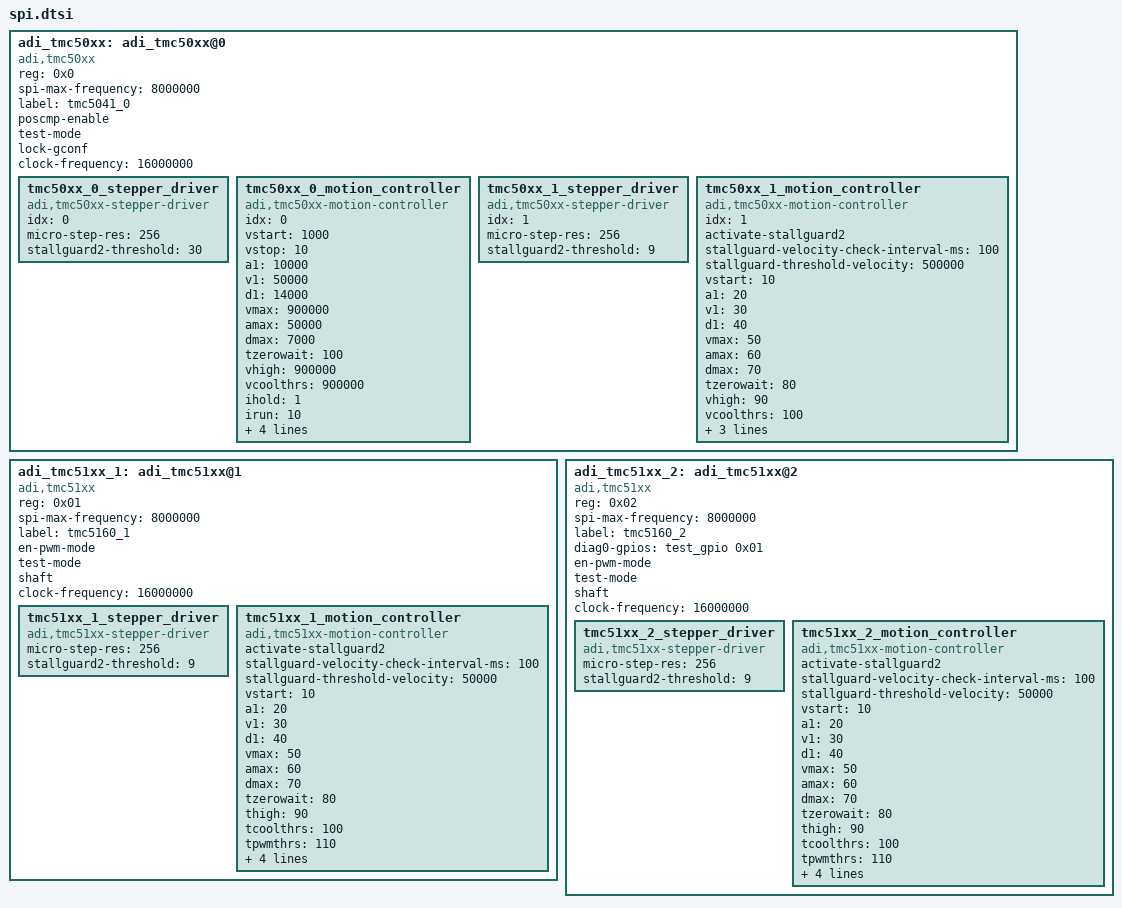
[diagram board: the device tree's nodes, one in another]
/*
 * SPDX-FileCopyrightText: Copyright (c) 2024 Carl Zeiss Meditec AG
 * SPDX-License-Identifier: Apache-2.0
 */
/****************************************
 * PLEASE KEEP REG ADDRESSES SEQUENTIAL *
 ***************************************/

#include <zephyr/dt-bindings/gpio/gpio.h>

adi_tmc50xx: adi_tmc50xx@0 {
	compatible = "adi,tmc50xx";
	status = "okay";
	reg = <0x0>;
	spi-max-frequency = <8000000>;
	label = "tmc5041_0";

	poscmp-enable; test-mode; lock-gconf; /* ADI TMC Global configuration flags */
	clock-frequency = <16000000>; /* Internal/External Clock frequency */

	/* common stepper controller settings */
	tmc50xx_0_stepper_driver: tmc50xx_0_stepper_driver {
		idx = <0>;
		compatible = "adi,tmc50xx-stepper-driver";
		micro-step-res = <256>;
		/* ADI TMC stallguard settings specific to TMC50XX */
		stallguard2-threshold=<30>;
	};

	/* ADI TMC ramp generator as well as current settings */
	tmc50xx_0_motion_controller: tmc50xx_0_motion_controller {
		idx = <0>;
		compatible = "adi,tmc50xx-motion-controller";
		vstart = <1000>;
		vstop = <10>;
		a1 = <10000>;
		v1 = <50000>;
		d1 = <14000>;
		vmax = <900000>;
		amax = <50000>;
		dmax = <7000>;
		tzerowait = <100>;
		vhigh = <900000>;
		vcoolthrs = <900000>;
		ihold = <1>;
		irun = <10>;
		iholddelay = <1>;
		activate-stallguard2;
		stallguard-velocity-check-interval-ms=<1000>;
		stallguard-threshold-velocity=<200000>;
	};

	/* common stepper controller settings */
	tmc50xx_1_stepper_driver: tmc50xx_1_stepper_driver {
		idx = <1>;
		compatible = "adi,tmc50xx-stepper-driver";
		micro-step-res = <256>;
		/* ADI TMC stallguard settings specific to TMC50XX */
		stallguard2-threshold=<9>;
	};

	tmc50xx_1_motion_controller: tmc50xx_1_motion_controller {
		idx = <1>;
		/* ADI TMC stallguard settings specific to TMC50XX */
		compatible = "adi,tmc50xx-motion-controller";
		activate-stallguard2;
		stallguard-velocity-check-interval-ms=<100>;
		stallguard-threshold-velocity=<500000>;

		/* ADI TMC ramp generator as well as current settings */
		vstart = <10>;
		a1 = <20>;
		v1 = <30>;
		d1 = <40>;
		vmax = <50>;
		amax = <60>;
		dmax = <70>;
		tzerowait = <80>;
		vhigh = <90>;
		vcoolthrs = <100>;
		ihold = <1>;
		irun = <2>;
		iholddelay = <3>;
	};
};

adi_tmc51xx_1: adi_tmc51xx@1 {
	compatible = "adi,tmc51xx";
	status = "okay";
	reg = <0x01>;
	spi-max-frequency = <8000000>;
	label = "tmc5160_1";

	en-pwm-mode; test-mode; shaft; /* ADI TMC Global configuration flags */
	clock-frequency = <16000000>; /* Internal/External Clock frequency */

	tmc51xx_1_stepper_driver: tmc51xx_1_stepper_driver {
		compatible = "adi,tmc51xx-stepper-driver";
		micro-step-res = <256>;
		/* ADI TMC stallguard settings specific to TMC51XX */
		stallguard2-threshold=<9>;
	};
	/* common stepper controller settings */
	tmc51xx_1_motion_controller: tmc51xx_1_motion_controller {
		compatible = "adi,tmc51xx-motion-controller";

		/* ADI TMC stallguard settings specific to TMC5160 */
		activate-stallguard2;
		stallguard-velocity-check-interval-ms = <100>;
		stallguard-threshold-velocity = <50000>;

		/* ADI TMC ramp generator as well as current settings */
		vstart = <10>;
		a1 = <20>;
		v1 = <30>;
		d1 = <40>;
		vmax = <50>;
		amax = <60>;
		dmax = <70>;
		tzerowait = <80>;
		thigh = <90>;
		tcoolthrs = <100>;
		tpwmthrs = <110>;
		tpowerdown = <120>;
		ihold = <1>;
		irun = <2>;
		iholddelay = <3>;
	};
};

adi_tmc51xx_2: adi_tmc51xx@2 {
	compatible = "adi,tmc51xx";
	status = "okay";
	reg = <0x02>;
	spi-max-frequency = <8000000>;
	label = "tmc5160_2";

	diag0-gpios = <&test_gpio 0x01 (GPIO_ACTIVE_HIGH | GPIO_PULL_UP)>; /* DIAG pin @0x01 */

	en-pwm-mode; test-mode; shaft; /* ADI TMC Global configuration flags */
	clock-frequency = <16000000>; /* Internal/External Clock frequency */

	tmc51xx_2_stepper_driver: tmc51xx_2_stepper_driver {
		compatible = "adi,tmc51xx-stepper-driver";
		micro-step-res = <256>;
		/* ADI TMC stallguard settings specific to TMC51XX */
		stallguard2-threshold=<9>;
	};
	/* common stepper controller settings */
	tmc51xx_2_motion_controller: tmc51xx_2_motion_controller {
		compatible = "adi,tmc51xx-motion-controller";

		/* ADI TMC stallguard settings specific to TMC5160 */
		activate-stallguard2;
		stallguard-velocity-check-interval-ms = <100>;
		stallguard-threshold-velocity = <50000>;

		/* ADI TMC ramp generator as well as current settings */
		vstart = <10>;
		a1 = <20>;
		v1 = <30>;
		d1 = <40>;
		vmax = <50>;
		amax = <60>;
		dmax = <70>;
		tzerowait = <80>;
		thigh = <90>;
		tcoolthrs = <100>;
		tpwmthrs = <110>;
		tpowerdown = <120>;
		ihold = <1>;
		irun = <2>;
		iholddelay = <3>;
	};
};
